# sysctl register map
Vendor: Texas Instruments
Peripheral module from a debugger description file (folder MSP432).
Registers are 32-bit, read-write, no defined reset value unless marked. A register's access mark holds for its fields unless they carry their own. Offsets are as the file gives them; lines under a group give offsets from that group; [hi:lo] are bit positions; {n}, {i} and the like mark numbered series; 'fields as' and 'values as' point back to an identical list; <NAME> marks a mode.

## SYSCTL
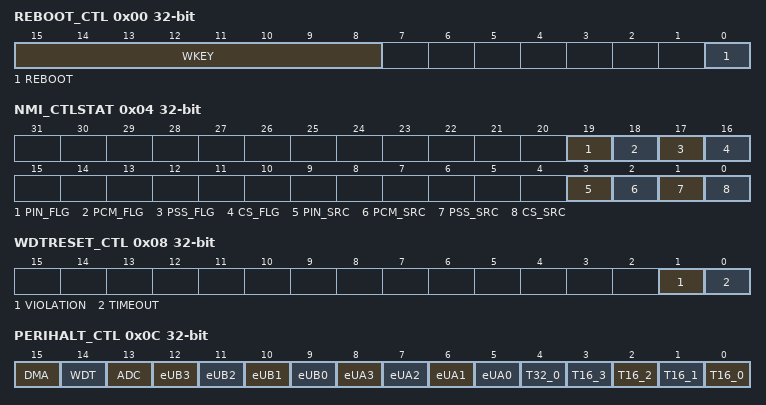
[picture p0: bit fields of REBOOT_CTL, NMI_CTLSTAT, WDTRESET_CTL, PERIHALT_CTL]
0x00 REBOOT_CTL — Reboot Control Register
  [15:8] WKEY — Key to enable writes to bit 0
  [0] REBOOT — Write 1 initiates a Reboot of the device
0x04 NMI_CTLSTAT — NMI Control and Status Register
  [19] PIN_FLG — Indicates if RSTn/NMI pin was the source of NMI
    0=PIN_FLG__0 (Indicates the RSTn_NMI pin was not the source of NMI); 1=PIN_FLG__1 (Indicates the RSTn_NMI pin was the source of NMI)
  [18] PCM_FLG — This flag gets auto-cleared when the corresponding source flag
    0=PCM_FLG__0 (indicates the PCM interrupt was not the source of NMI); 1=PCM_FLG__1 (indicates the PCM interrupt was the source of NMI)
  [17] PSS_FLG — This flag gets auto-cleared when the corresponding source flag
    0=PSS_FLG__0 (indicates the PSS interrupt was not the source of NMI); 1=PSS_FLG__1 (indicates the PSS interrupt was the source of NMI)
  [16] CS_FLG — This flag gets auto-cleared when the corresponding source flag
    0=CS_FLG__0 (indicates CS interrupt was not the source of NMI); 1=CS_FLG__1 (indicates CS interrupt was the source of NMI)
  [3] PIN_SRC — RSTn/NMI pin configuration Note: When the device enters LPM3/L
    0=PIN_SRC__0 (Configures the RSTn_NMI pin as a source of POR Class Reset); 1=PIN_SRC__1 (Configures the RSTn_NMI pin as a source of NMI)
  [2] PCM_SRC — PCM interrupt as a source of NMI
    0=PCM_SRC__0 (Disbles the PCM interrupt as a source of NMI); 1=PCM_SRC__1 (Enables the PCM interrupt as a source of NMI)
  [1] PSS_SRC — PSS interrupt as a source of NMI
    0=PSS_SRC__0 (Disables the PSS interrupt as a source of NMI); 1=PSS_SRC__1 (Enables the PSS interrupt as a source of NMI)
  [0] CS_SRC — CS interrupt as a source of NMI
    0=CS_SRC__0 (Disables CS interrupt as a source of NMI); 1=CS_SRC__1 (Enables CS interrupt as a source of NMI)
0x08 WDTRESET_CTL — Watchdog Reset Control Register
  [1] VIOLATION — WDT password violation reset type
    0=VIOLATION__0 (WDT password violation event generates Soft reset); 1=VIOLATION__1 (WDT password violation event generates Hard reset)
  [0] TIMEOUT — WDT timeout reset type
    0=TIMEOUT__0 (WDT timeout event generates Soft reset); 1=TIMEOUT__1 (WDT timeout event generates Hard reset)
0x0C PERIHALT_CTL — Peripheral Halt Control Register
  [15] DMA
    0=DMA__0 (IP operation unaffected when CPU is halted); 1=DMA__1 (freezes IP operation when CPU is halted)
  [14] WDT
    0=WDT__0 (IP operation unaffected when CPU is halted); 1=WDT__1 (freezes IP operation when CPU is halted)
  [13] ADC
    0=ADC__0 (IP operation unaffected when CPU is halted); 1=ADC__1 (freezes IP operation when CPU is halted)
  [n+9] eUB{n} (n=0..3)
    0=eUB{n}__0 (IP operation unaffected when CPU is halted); 1=eUB{n}__1 (freezes IP operation when CPU is halted)
  [n+5] eUA{n} (n=0..3)
    0=eUA{n}__0 (IP operation unaffected when CPU is halted); 1=eUA{n}__1 (freezes IP operation when CPU is halted)
  [4] T32_0
    0=T32_0__0 (IP operation unaffected when CPU is halted); 1=T32_0__1 (freezes IP operation when CPU is halted)
  [n] T16_{n} (n=0..3)
    0=T16_{n}__0 (IP operation unaffected when CPU is halted); 1=T16_{n}__1 (freezes IP operation when CPU is halted)
0x10 SRAM_SIZE
  [31:0] SIZE — Indicates the size of SRAM on the device
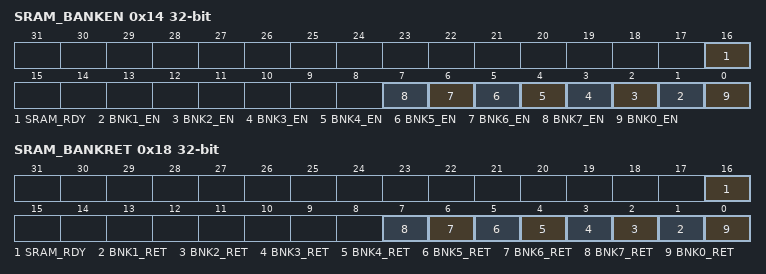
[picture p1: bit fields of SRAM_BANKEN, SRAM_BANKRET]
0x14 SRAM_BANKEN — SRAM Bank Enable Register
  [16] SRAM_RDY — This bit will automatically be set to '0' whenever any of the B
    0=SRAM_RDY__0 (SRAM is not ready for accesses); 1=SRAM_RDY__1 (SRAM is ready for accesses)
  [n] BNK{n}_EN (n=1..7) — When set to 1, bank enable bits for all banks below this bank a
    0=BNK{n}_EN__0 (Disables Bank{n} of the SRAM); 1=BNK{n}_EN__1 (Enables Bank{n} of the SRAM)
  [0] BNK0_EN — When 1, enables Bank0 of the SRAM
0x18 SRAM_BANKRET — SRAM Bank Retention Control Register
  [16] SRAM_RDY — This bit will automatically be set to '0' whenever any of the B
    0=SRAM_RDY__0 (SRAM banks are being set up for retention); 1=SRAM_RDY__1 (SRAM is ready for accesses)
  [n] BNK{n}_RET (n=1..7) — Value of this bit is a don't care in when the device enters LPM
    0=BNK{n}_RET__0 (Bank{n} of the SRAM is not retained in LPM3 or LPM4); 1=BNK{n}_RET__1 (Bank{n} of the SRAM is retained in LPM3 and LPM4)
  [0] BNK0_RET — Bank0 is always retained in LPM3, LPM4 and LPM3
0x20 FLASH_SIZE
  [31:0] SIZE — Indicates the size of the Flash main memory on the device
0x30 DIO_GLTFLT_CTL — Digital I/O Glitch Filter Control Register
  [0] GLTCH_EN
    0=GLTCH_EN__0 (Disables glitch filter on the digital I/Os); 1=GLTCH_EN__1 (Enables glitch filter on the digital I/Os)
0x40 SECDATA_UNLOCK — IP Protected Secure Zone Data Access Unlock Register
  [15:0] UNLKEY — Unlock Key, which requests for IP protected secure zone to be u
